# AT90CAN128 device description
Architecture: AVR8; Family: megaAVR
Registers are 8-bit, access not given, no defined reset value unless marked. A register's access mark holds for its fields unless they carry their own. Offsets are from the block's base; [hi:lo] are bit positions.

## LOCKBIT — Lockbits
Instances: LOCKBIT 0 in lockbits
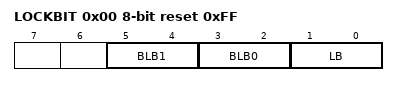
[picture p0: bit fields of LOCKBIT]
0x00 LOCKBIT reset 0xFF
  [5:4] BLB1 — Boot Loader Protection Mode
    0=LPM_SPM_DISABLE (LPM and SPM prohibited in Boot Section); 1=LPM_DISABLE (LPM prohibited in Boot Section); 2=SPM_DISABLE (SPM prohibited in Boot Section); 3=NO_LOCK (No lock on SPM and LPM in Boot Section)
  [3:2] BLB0 — Boot Loader Protection Mode
    0=LPM_SPM_DISABLE (LPM and SPM prohibited in Application Section); 1=LPM_DISABLE (LPM prohibited in Application Section); 2=SPM_DISABLE (SPM prohibited in Application Section); 3=NO_LOCK (No lock on SPM and LPM in Application Section)
  [1:0] LB — Memory Lock
    0=PROG_VER_DISABLED (Further programming and verification disabled); 2=PROG_DISABLED (Further programming disabled); 3=NO_LOCK (No memory lock features enabled)

## PORTA — I/O Port
Instances: PORTA 0x00
0x20 PINA — Port A Input Pins
0x21 DDRA — Port A Data Direction Register
0x22 PORTA — Port A Data Register

## PORTB — I/O Port
Instances: PORTB 0x00
0x23 PINB — Port B Input Pins
0x24 DDRB — Port B Data Direction Register
0x25 PORTB — Port B Data Register

## PORTC — I/O Port
Instances: PORTC 0x00
0x26 PINC — Port C Input Pins
0x27 DDRC — Port C Data Direction Register
0x28 PORTC — Port C Data Register

## PORTD — I/O Port
Instances: PORTD 0x00
0x29 PIND — Port D Input Pins
0x2A DDRD — Port D Data Direction Register
0x2B PORTD — Port D Data Register

## PORTE — I/O Port
Instances: PORTE 0x00
0x2C PINE — Input Pins, Port E
0x2D DDRE — Data Direction Register, Port E
0x2E PORTE — Data Register, Port E

## PORTF — I/O Port
Instances: PORTF 0x00
0x2F PINF — Input Pins, Port F
0x30 DDRF — Data Direction Register, Port F
0x31 PORTF — Data Register, Port F

## PORTG — I/O Port
Instances: PORTG 0x00
0x32 PING bits used 4:0 — Input Pins, Port G
0x33 DDRG bits used 4:0 — Data Direction Register, Port G
0x34 PORTG bits used 4:0 — Data Register, Port G

## JTAG — JTAG Interface
Instances: JTAG 0x00
0x51 OCDR — On-Chip Debug Related Register in I/O Memory
0x54 MCUSR — MCU Status Register
  [4] JTRF — JTAG Reset Flag
0x55 MCUCR — MCU Control Register
  [7] JTD — JTAG Interface Disable

## SPI — Serial Peripheral Interface
Instances: SPI 0x00
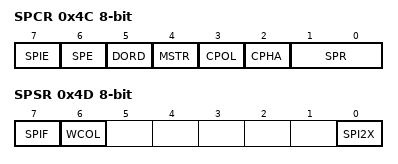
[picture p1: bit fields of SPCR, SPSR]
0x4C SPCR — SPI Control Register
  [7] SPIE — SPI Interrupt Enable
  [6] SPE — SPI Enable
  [5] DORD — Data Order
  [4] MSTR — Master/Slave Select
  [3] CPOL — Clock polarity
  [2] CPHA — Clock Phase
  [1:0] SPR — SPI Clock Rate Selects
    0=FOSC_4; 1=FOSC_16; 2=FOSC_64; 3=FOSC_128; 4=FOSC_2; 5=FOSC_8; 6=FOSC_32; 7=FOSC_64
0x4D SPSR — SPI Status Register
  [7] SPIF — SPI Interrupt Flag
  [6] WCOL — Write Collision Flag
  [0] SPI2X — Double SPI Speed Bit
0x4E SPDR — SPI Data Register
  [7:0] SPD

## TWI — Two Wire Serial Interface
Instances: TWI 0x00
0xB8 TWBR — TWI Bit Rate register
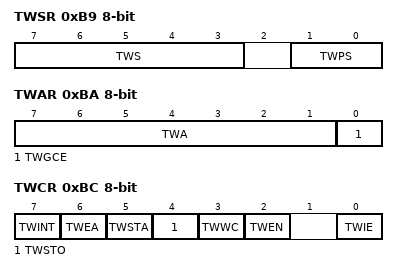
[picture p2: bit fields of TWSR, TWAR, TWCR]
0xB9 TWSR — TWI Status Register
  [7:3] TWS (bit 3 of the value upward) — TWI Status
  [1:0] TWPS — TWI Prescaler
    0=1; 1=4; 2=16; 3=64
0xBA TWAR — TWI (Slave) Address register
  [7:1] TWA — TWI (Slave) Address register Bits
  [0] TWGCE — TWI General Call Recognition Enable Bit
0xBB TWDR — TWI Data register
0xBC TWCR — TWI Control Register
  [7] TWINT — TWI Interrupt Flag
  [6] TWEA — TWI Enable Acknowledge Bit
  [5] TWSTA — TWI Start Condition Bit
  [4] TWSTO — TWI Stop Condition Bit
  [3] TWWC — TWI Write Collision Flag
  [2] TWEN — TWI Enable Bit
  [0] TWIE — TWI Interrupt Enable

## USART0 — USART
Instances: USART0 0x00
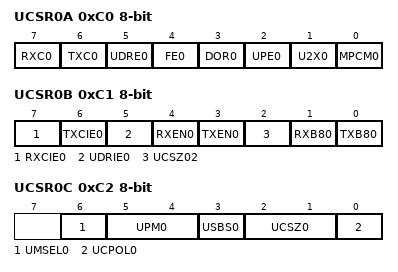
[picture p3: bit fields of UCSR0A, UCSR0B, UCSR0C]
0xC0 UCSR0A — USART Control and Status Register A
  [7] RXC0 ro — USART Receive Complete
  [6] TXC0 — USART Transmit Complete
  [5] UDRE0 ro — USART Data Register Empty
  [4] FE0 ro — Framing Error
  [3] DOR0 ro — Data overRun
  [2] UPE0 ro — Parity Error
  [1] U2X0 — Double the USART transmission speed
  [0] MPCM0 — Multi-processor Communication Mode
0xC1 UCSR0B — USART Control and Status Register B
  [7] RXCIE0 — RX Complete Interrupt Enable
  [6] TXCIE0 — TX Complete Interrupt Enable
  [5] UDRIE0 — USART Data register Empty Interrupt Enable
  [4] RXEN0 — Receiver Enable
  [3] TXEN0 — Transmitter Enable
  [2] UCSZ02 — Character Size
  [1] RXB80 — Receive Data Bit 8
  [0] TXB80 — Transmit Data Bit 8
0xC2 UCSR0C — USART Control and Status Register C
  [6] UMSEL0 — USART Mode Select
    0=ASYNCHRONOUS_OPERATION; 1=SYNCHRONOUS_OPERATION
  [5:4] UPM0 — Parity Mode Bits
    0=DISABLED; 2=ENABLED_EVEN_PARITY; 3=ENABLED_ODD_PARITY
  [3] USBS0 — Stop Bit Select
    0=1_BIT; 1=2_BIT
  [2:1] UCSZ0 — Character Size
  [0] UCPOL0 — Clock Polarity
0xC4 UBRR0 16-bit bits used 11:0 — USART Baud Rate Register t Bytes
0xC6 UDR0 — USART I/O Data Register
